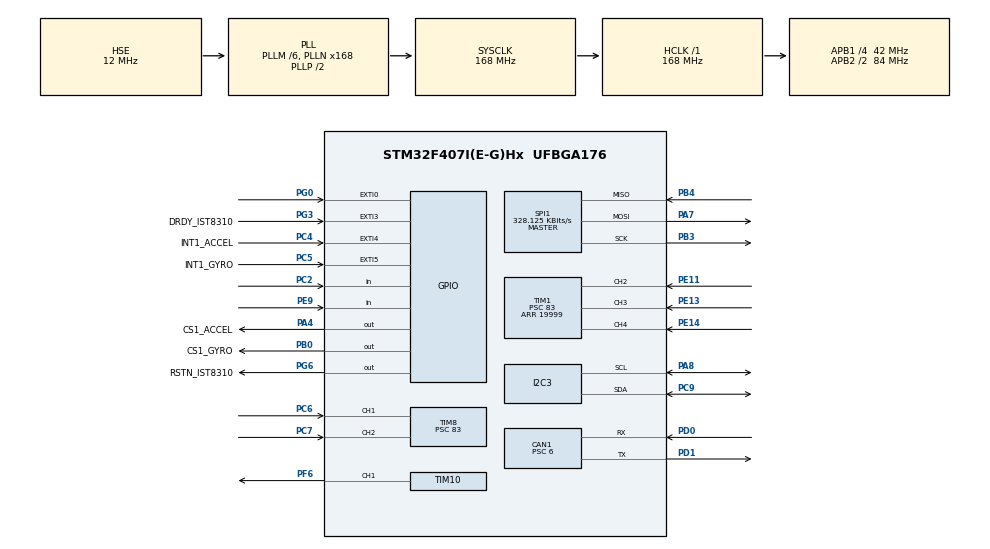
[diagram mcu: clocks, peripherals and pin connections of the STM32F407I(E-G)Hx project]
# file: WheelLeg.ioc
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CAN1.BS1=CAN_BS1_3TQ
CAN1.BS2=CAN_BS2_3TQ
CAN1.CalculateBaudRate=1000000
CAN1.CalculateTimeBit=1000
CAN1.CalculateTimeQuantum=142.85714285714286
CAN1.Prescaler=6
Dma.Request0=SPI1_RX
Dma.Request1=SPI1_TX
Dma.SPI1_RX.0.Direction=DMA_PERIPH_TO_MEMORY
Dma.SPI1_RX.0.FIFOMode=DMA_FIFOMODE_DISABLE
Dma.SPI1_RX.0.Instance=DMA2_Stream2
Dma.SPI1_RX.0.MemDataAlignment=DMA_MDATAALIGN_BYTE
Dma.SPI1_RX.0.MemInc=DMA_MINC_ENABLE
Dma.SPI1_RX.0.Mode=DMA_NORMAL
Dma.SPI1_RX.0.PeriphDataAlignment=DMA_PDATAALIGN_BYTE
Dma.SPI1_RX.0.PeriphInc=DMA_PINC_DISABLE
Dma.SPI1_RX.0.Priority=DMA_PRIORITY_VERY_HIGH
Dma.SPI1_TX.1.Direction=DMA_MEMORY_TO_PERIPH
Dma.SPI1_TX.1.FIFOMode=DMA_FIFOMODE_DISABLE
Dma.SPI1_TX.1.Instance=DMA2_Stream3
Dma.SPI1_TX.1.MemDataAlignment=DMA_MDATAALIGN_BYTE
Dma.SPI1_TX.1.MemInc=DMA_MINC_ENABLE
Dma.SPI1_TX.1.Mode=DMA_NORMAL
Dma.SPI1_TX.1.PeriphDataAlignment=DMA_PDATAALIGN_BYTE
Dma.SPI1_TX.1.PeriphInc=DMA_PINC_DISABLE
Dma.SPI1_TX.1.Priority=DMA_PRIORITY_HIGH
FREERTOS.INCLUDE_vTaskDelayUntil=1
FREERTOS.INCLUDE_xTaskGetHandle=1
FREERTOS.Tasks01=StartTask,0,512,StartInitTask,As weak,NULL,Dynamic,NULL,NULL
I2C3.I2C_Mode=I2C_Fast
Mcu.Family=STM32F4
Mcu.Name=STM32F407I(E-G)Hx
Mcu.Package=UFBGA176
NVIC.CAN1_RX0_IRQn=true\:5\:0\:true\:false\:true\:true\:true\:true\:true
NVIC.DMA2_Stream2_IRQn=true\:5\:0\:false\:false\:false\:true\:false\:true\:true
NVIC.DMA2_Stream3_IRQn=true\:5\:0\:false\:false\:false\:true\:false\:true\:true
NVIC.EXTI0_IRQn=true\:6\:0\:true\:false\:true\:true\:true\:true\:true
NVIC.EXTI3_IRQn=true\:5\:0\:false\:false\:true\:true\:true\:true\:true
NVIC.EXTI4_IRQn=true\:5\:0\:false\:false\:true\:true\:true\:true\:true
NVIC.EXTI9_5_IRQn=true\:5\:0\:false\:false\:true\:true\:true\:true\:true
NVIC.PriorityGroup=NVIC_PRIORITYGROUP_4
NVIC.TIM1_CC_IRQn=true\:6\:0\:true\:false\:true\:true\:true\:true\:true
NVIC.TIM8_CC_IRQn=true\:6\:0\:true\:false\:true\:true\:true\:true\:true
PA13.Mode=Serial_Wire
PA13.Signal=SYS_JTMS-SWDIO
PA14.Mode=Serial_Wire
PA14.Signal=SYS_JTCK-SWCLK
PA4.GPIO_Label=CS1_ACCEL
PA4.GPIO_PuPd=GPIO_PULLUP
PA4.GPIO_Speed=GPIO_SPEED_FREQ_HIGH
PA4.PinState=GPIO_PIN_SET
PA4.Signal=GPIO_Output
PA7.GPIO_PuPd=GPIO_PULLUP
PA7.Mode=Full_Duplex_Master
PA7.Signal=SPI1_MOSI
PA8.GPIO_Pu=GPIO_PULLUP
PA8.Mode=I2C
PA8.Signal=I2C3_SCL
PB0.GPIO_Label=CS1_GYRO
PB0.GPIO_PuPd=GPIO_PULLUP
PB0.GPIO_Speed=GPIO_SPEED_FREQ_HIGH
PB0.PinState=GPIO_PIN_SET
PB0.Signal=GPIO_Output
PB3.GPIO_PuPd=GPIO_PULLUP
PB3.Mode=Full_Duplex_Master
PB3.Signal=SPI1_SCK
PB4.GPIO_PuPd=GPIO_PULLUP
PB4.Mode=Full_Duplex_Master
PB4.Signal=SPI1_MISO
PC2.Signal=GPIO_Input
PC4.GPIO_Label=INT1_ACCEL
PC4.GPIO_ModeDefaultEXTI=GPIO_MODE_IT_FALLING
PC4.GPIO_PuPd=GPIO_PULLUP
PC4.Signal=GPXTI4
PC5.GPIO_Label=INT1_GYRO
PC5.GPIO_ModeDefaultEXTI=GPIO_MODE_IT_FALLING
PC5.GPIO_PuPd=GPIO_PULLUP
PC5.Signal=GPXTI5
PC6.GPIO_Speed=GPIO_SPEED_FREQ_VERY_HIGH
PC6.Signal=S_TIM8_CH1
PC7.GPIO_Speed=GPIO_SPEED_FREQ_VERY_HIGH
PC7.Signal=S_TIM8_CH2
PC9.GPIO_Pu=GPIO_PULLUP
PC9.Mode=I2C
PC9.Signal=I2C3_SDA
PD0.Mode=CAN_Activate
PD0.Signal=CAN1_RX
PD1.Mode=CAN_Activate
PD1.Signal=CAN1_TX
PE11.GPIO_Speed=GPIO_SPEED_FREQ_VERY_HIGH
PE11.Signal=S_TIM1_CH2
PE13.GPIO_Speed=GPIO_SPEED_FREQ_VERY_HIGH
PE13.Signal=S_TIM1_CH3
PE14.GPIO_Speed=GPIO_SPEED_FREQ_VERY_HIGH
PE14.Signal=S_TIM1_CH4
PE9.Signal=GPIO_Input
PF6.GPIO_PuPd=GPIO_PULLUP
PF6.GPIO_Speed=GPIO_SPEED_FREQ_HIGH
PF6.Signal=S_TIM10_CH1
PG0.GPIO_ModeDefaultEXTI=GPIO_MODE_IT_FALLING
PG0.GPIO_PuPd=GPIO_PULLUP
PG0.Signal=GPXTI0
PG3.GPIO_Label=DRDY_IST8310
PG3.GPIO_ModeDefaultEXTI=GPIO_MODE_IT_FALLING
PG3.GPIO_PuPd=GPIO_PULLUP
PG3.Signal=GPXTI3
PG6.GPIO_Label=RSTN_IST8310
PG6.GPIO_PuPd=GPIO_PULLUP
PG6.GPIO_Speed=GPIO_SPEED_FREQ_MEDIUM
PG6.PinState=GPIO_PIN_SET
PG6.Signal=GPIO_Output
PH0-OSC_IN.Mode=HSE-External-Oscillator
PH0-OSC_IN.Signal=RCC_OSC_IN
PH1-OSC_OUT.Mode=HSE-External-Oscillator
PH1-OSC_OUT.Signal=RCC_OSC_OUT
ProjectManager.HeapSize=0x2000
ProjectManager.StackSize=0x2000
ProjectManager.TargetToolchain=MDK-ARM V5.32
RCC.48MHZClocksFreq_Value=84000000
RCC.AHBFreq_Value=168000000
RCC.APB1CLKDivider=RCC_HCLK_DIV4
RCC.APB1Freq_Value=42000000
RCC.APB1TimFreq_Value=84000000
RCC.APB2CLKDivider=RCC_HCLK_DIV2
RCC.APB2Freq_Value=84000000
RCC.APB2TimFreq_Value=168000000
RCC.CortexFreq_Value=168000000
RCC.HCLKFreq_Value=168000000
RCC.HSE_VALUE=12000000
RCC.HSI_VALUE=16000000
RCC.LSE_VALUE=32768
RCC.PLLM=6
RCC.PLLN=168
RCC.PLLSourceVirtual=RCC_PLLSOURCE_HSE
RCC.SYSCLKFreq_VALUE=168000000
RCC.SYSCLKSource=RCC_SYSCLKSOURCE_PLLCLK
RCC.VCOOutputFreq_Value=336000000
SH.S_TIM10_CH1.0=TIM10_CH1,PWM Generation1 CH1
SH.S_TIM1_CH2.0=TIM1_CH2,Input_Capture2_from_TI2
SH.S_TIM1_CH3.0=TIM1_CH3,Input_Capture3_from_TI3
SH.S_TIM1_CH4.0=TIM1_CH4,Input_Capture4_from_TI4
SH.S_TIM8_CH1.0=TIM8_CH1,Input_Capture1_from_TI1
SH.S_TIM8_CH2.0=TIM8_CH2,Input_Capture2_from_TI2
SPI1.BaudRatePrescaler=SPI_BAUDRATEPRESCALER_256
SPI1.CLKPhase=SPI_PHASE_2EDGE
SPI1.CLKPolarity=SPI_POLARITY_HIGH
SPI1.CalculateBaudRate=328.125 KBits/s
SPI1.Direction=SPI_DIRECTION_2LINES
SPI1.Mode=SPI_MODE_MASTER
SPI1.VirtualType=VM_MASTER
STMicroelectronics.X-CUBE-ALGOBUILD.1.4.0.LibraryCcDSPOoLibraryJjDSPOoLibrary=true
TIM1.AutoReloadPreload=TIM_AUTORELOAD_PRELOAD_ENABLE
TIM1.Channel-Input_Capture2_from_TI2=TIM_CHANNEL_2
TIM1.Channel-Input_Capture3_from_TI3=TIM_CHANNEL_3
TIM1.Channel-Input_Capture4_from_TI4=TIM_CHANNEL_4
TIM1.Period=19999
TIM1.Prescaler=83
TIM10.Channel=TIM_CHANNEL_1
TIM10.Period=4999
TIM2.AutoReloadPreload=TIM_AUTORELOAD_PRELOAD_ENABLE
TIM2.Period=0xFFFFFFF
TIM2.Prescaler=83
TIM8.AutoReloadPreload=TIM_AUTORELOAD_PRELOAD_ENABLE
TIM8.Channel-Input_Capture1_from_TI1=TIM_CHANNEL_1
TIM8.Channel-Input_Capture2_from_TI2=TIM_CHANNEL_2
TIM8.Period=19999
TIM8.Prescaler=83
VP_FREERTOS_VS_CMSIS_V1.Mode=CMSIS_V1
VP_STMicroelectronics.X-CUBE-ALGOBUILD_VS_DSPOoLibraryJjLibrary_1.4.0_1.4.0.Mode=DSPOoLibraryJjLibrary
VP_TIM10_VS_ClockSourceINT.Mode=Enable_Timer
VP_TIM1_VS_ClockSourceINT.Mode=Internal
VP_TIM2_VS_ClockSourceINT.Mode=Internal
VP_TIM8_VS_ClockSourceINT.Mode=Internal
board=custom

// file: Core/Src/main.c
/* USER CODE BEGIN Header */
/**
  ******************************************************************************
  * @file           : main.c
  * @brief          : Main program body
  ******************************************************************************
  * @attention
  *
  * Copyright (c) 2024 STMicroelectronics.
  * All rights reserved.
  *
  * This software is licensed under terms that can be found in the LICENSE file
  * in the root directory of this software component.
  * If no LICENSE file comes with this software, it is provided AS-IS.
  *
  ******************************************************************************
  */
/* USER CODE END Header */
#include "main.h"
#include "cmsis_os.h"
#include "can.h"
#include "dma.h"
#include "i2c.h"
#include "spi.h"
#include "tim.h"
#include "gpio.h"

void SystemClock_Config(void);
void MX_FREERTOS_Init(void);

int main(void)
{

  /* MCU Configuration--------------------------------------------------------*/

  /* Reset of all peripherals, Initializes the Flash interface and the Systick. */
  HAL_Init();

  /* Configure the system clock */
  SystemClock_Config();

  /* USER CODE BEGIN SysInit */
    // 启用 DWT 寄存�?
    if (!(CoreDebug->DEMCR & CoreDebug_DEMCR_TRCENA_Msk)) {
        CoreDebug->DEMCR |= CoreDebug_DEMCR_TRCENA_Msk;   // 启用 DWT 功能
    }
    DWT->CYCCNT = 0;    // 重置计数�?
    DWT->CTRL |= DWT_CTRL_CYCCNTENA_Msk;  // 启用 CYCCNT 计数�?

  /* USER CODE END SysInit */

  /* Initialize all configured peripherals */
  MX_GPIO_Init();
  MX_DMA_Init();
  MX_SPI1_Init();
  MX_TIM10_Init();
  MX_CAN1_Init();
  MX_I2C3_Init();
  MX_TIM2_Init();
  MX_TIM8_Init();
  MX_TIM1_Init();

  /* Call init function for freertos objects (in cmsis_os2.c) */
  MX_FREERTOS_Init();

  /* Start scheduler */
  osKernelStart();

  /* We should never get here as control is now taken by the scheduler */

  /* Infinite loop */
  while (1)
  {

  }
}

void SystemClock_Config(void)
{
  RCC_OscInitTypeDef RCC_OscInitStruct = {0};
  RCC_ClkInitTypeDef RCC_ClkInitStruct = {0};

  /** Configure the main internal regulator output voltage
  */
  __HAL_RCC_PWR_CLK_ENABLE();
  __HAL_PWR_VOLTAGESCALING_CONFIG(PWR_REGULATOR_VOLTAGE_SCALE1);

  /** Initializes the RCC Oscillators according to the specified parameters
  * in the RCC_OscInitTypeDef structure.
  */
  RCC_OscInitStruct.OscillatorType = RCC_OSCILLATORTYPE_HSE;
  RCC_OscInitStruct.HSEState = RCC_HSE_ON;
  RCC_OscInitStruct.PLL.PLLState = RCC_PLL_ON;
  RCC_OscInitStruct.PLL.PLLSource = RCC_PLLSOURCE_HSE;
  RCC_OscInitStruct.PLL.PLLM = 6;
  RCC_OscInitStruct.PLL.PLLN = 168;
  RCC_OscInitStruct.PLL.PLLP = RCC_PLLP_DIV2;
  RCC_OscInitStruct.PLL.PLLQ = 4;
  if (HAL_RCC_OscConfig(&RCC_OscInitStruct) != HAL_OK)
  {
    Error_Handler();
  }

  /** Initializes the CPU, AHB and APB buses clocks
  */
  RCC_ClkInitStruct.ClockType = RCC_CLOCKTYPE_HCLK|RCC_CLOCKTYPE_SYSCLK
                              |RCC_CLOCKTYPE_PCLK1|RCC_CLOCKTYPE_PCLK2;
  RCC_ClkInitStruct.SYSCLKSource = RCC_SYSCLKSOURCE_PLLCLK;
  RCC_ClkInitStruct.AHBCLKDivider = RCC_SYSCLK_DIV1;
  RCC_ClkInitStruct.APB1CLKDivider = RCC_HCLK_DIV4;
  RCC_ClkInitStruct.APB2CLKDivider = RCC_HCLK_DIV2;

  if (HAL_RCC_ClockConfig(&RCC_ClkInitStruct, FLASH_LATENCY_5) != HAL_OK)
  {
    Error_Handler();
  }
}

void Error_Handler(void)
{
  __disable_irq();
  while (1)
  {
  }
}

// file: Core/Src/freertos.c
/* USER CODE BEGIN Header */
/**
  ******************************************************************************
  * File Name          : freertos.c
  * Description        : Code for freertos applications
  ******************************************************************************
  * @attention
  *
  * Copyright (c) 2024 STMicroelectronics.
  * All rights reserved.
  *
  * This software is licensed under terms that can be found in the LICENSE file
  * in the root directory of this software component.
  * If no LICENSE file comes with this software, it is provided AS-IS.
  *
  ******************************************************************************
  */
/* USER CODE END Header */

#include "FreeRTOS.h"
#include "task.h"
#include "main.h"
#include "cmsis_os.h"

osThreadId StartTaskHandle;

void StartInitTask(void const * argument);

void MX_FREERTOS_Init(void); /* (MISRA C 2004 rule 8.1) */

/* GetIdleTaskMemory prototype (linked to static allocation support) */
void vApplicationGetIdleTaskMemory( StaticTask_t **ppxIdleTaskTCBBuffer, StackType_t **ppxIdleTaskStackBuffer, uint32_t *pulIdleTaskStackSize );

/* USER CODE BEGIN GET_IDLE_TASK_MEMORY */
static StaticTask_t xIdleTaskTCBBuffer;
static StackType_t xIdleStack[configMINIMAL_STACK_SIZE];

void vApplicationGetIdleTaskMemory( StaticTask_t **ppxIdleTaskTCBBuffer, StackType_t **ppxIdleTaskStackBuffer, uint32_t *pulIdleTaskStackSize )
{
  *ppxIdleTaskTCBBuffer = &xIdleTaskTCBBuffer;
  *ppxIdleTaskStackBuffer = &xIdleStack[0];
  *pulIdleTaskStackSize = configMINIMAL_STACK_SIZE;
  /* place for user code */
}
/* USER CODE END GET_IDLE_TASK_MEMORY */

void MX_FREERTOS_Init(void) {

  /* Create the thread(s) */
  /* definition and creation of StartTask */
  osThreadDef(StartTask, StartInitTask, osPriorityNormal, 0, 512);
  StartTaskHandle = osThreadCreate(osThread(StartTask), NULL);

}

__weak void StartInitTask(void const * argument)
{
  for(;;)
  {
    osDelay(1);
  }
}
